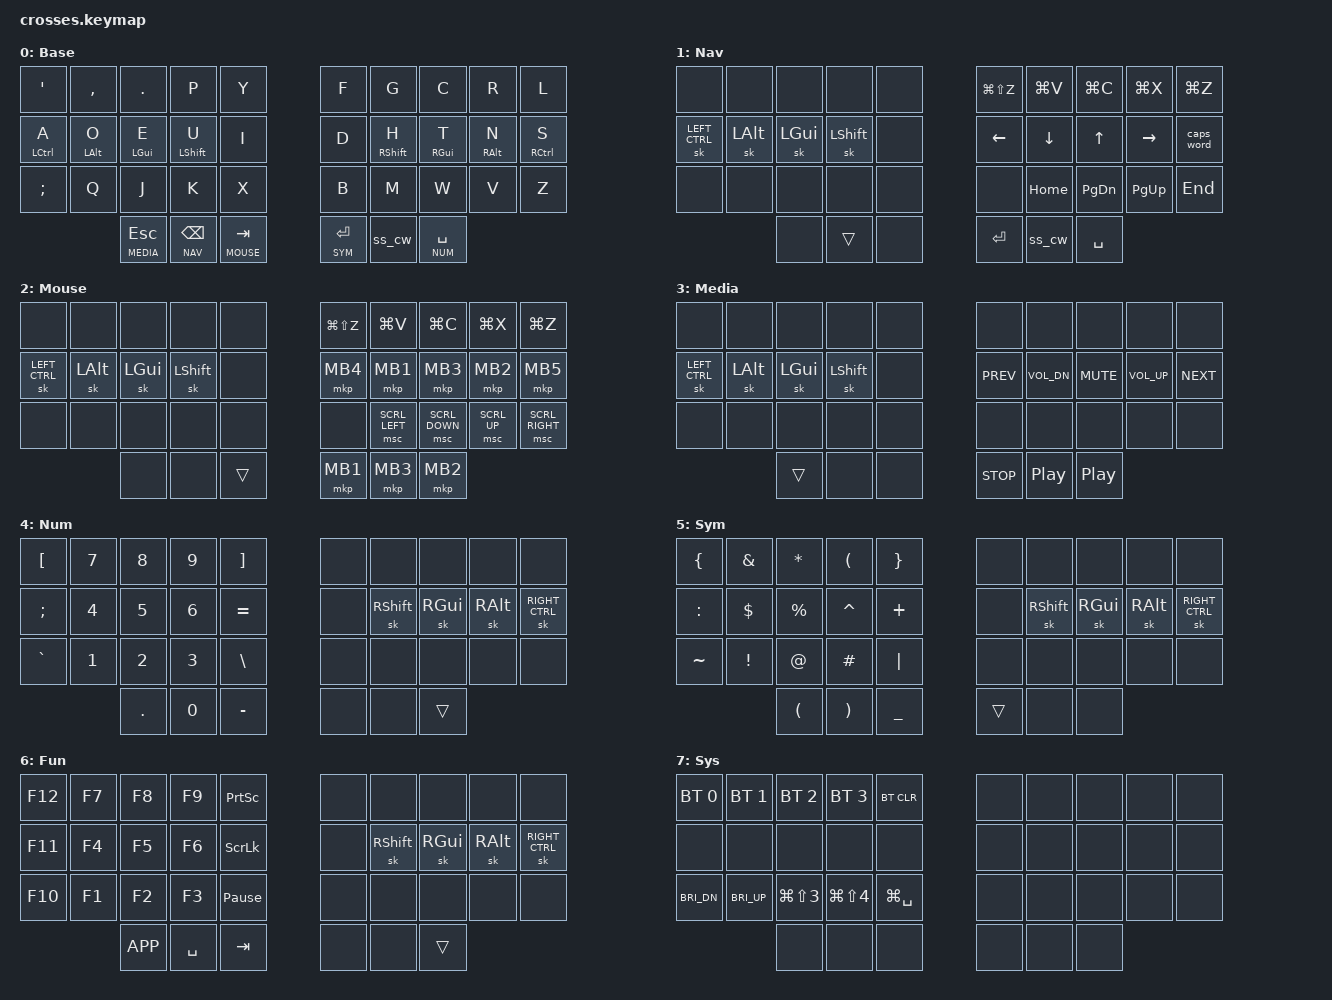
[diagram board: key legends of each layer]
#include <behaviors.dtsi>
#include <dt-bindings/zmk/bt.h>
#include <dt-bindings/zmk/keys.h>
#include <dt-bindings/zmk/pointing.h>

#define BASE  0
#define NAV   1
#define MOUSE 2
#define MEDIA 3
#define NUM   4
#define SYM   5
#define FUN   6
#define SYS   7

#define HM_TAPPING_TERM 280
#define HM_QUICK_TAP    175
#define HM_PRIOR_IDLE   150

/ {
    behaviors {

        hml: homerow_mod_left {
            compatible = "zmk,behavior-hold-tap";
            #binding-cells = <2>;
            flavor = "balanced";
            tapping-term-ms = <HM_TAPPING_TERM>;
            quick-tap-ms = <HM_QUICK_TAP>;
            require-prior-idle-ms = <HM_PRIOR_IDLE>;
            bindings = <&kp>, <&kp>;
            hold-trigger-key-positions = <5 6 7 8 9 15 16 17 18 19 25 26 27 28 29 30 31 32 33 34 35>;
            hold-trigger-on-release;
        };

        hmr: homerow_mod_right {
            compatible = "zmk,behavior-hold-tap";
            #binding-cells = <2>;
            flavor = "balanced";
            tapping-term-ms = <HM_TAPPING_TERM>;
            quick-tap-ms = <HM_QUICK_TAP>;
            require-prior-idle-ms = <HM_PRIOR_IDLE>;
            bindings = <&kp>, <&kp>;
            hold-trigger-key-positions = <0 1 2 3 4 10 11 12 13 14 20 21 22 23 24 30 31 32 33 34 35>;
            hold-trigger-on-release;
        };

        ss_cw: sticky_shift_caps_word {
            compatible = "zmk,behavior-mod-morph";
            #binding-cells = <0>;
            bindings = <&sk LEFT_SHIFT>, <&caps_word>;
            mods = <(MOD_LSFT)>;
        };

        lt_bspc: layer_tap_backspace {
            compatible = "zmk,behavior-hold-tap";
            #binding-cells = <2>;
            flavor = "balanced";
            tapping-term-ms = <200>;
            quick-tap-ms = <HM_QUICK_TAP>;
            bindings = <&mo>, <&kp>;
        };
    };

    conditional_layers {
        compatible = "zmk,conditional-layers";
        sys_layer {
            if-layers = <FUN NUM>;
            then-layer = <SYS>;
        };
    };

    keymap {
        compatible = "zmk,keymap";

        base_layer {
            display-name = "Base";
            bindings = 
   &kp SQT               &kp COMMA           &kp PERIOD          &kp P               &kp Y          &kp F        &kp G               &kp C            &kp R               &kp L
   &hml LEFT_CONTROL A   &hml LEFT_ALT O     &hml LEFT_GUI E     &hml LEFT_SHIFT U   &kp I          &kp D        &hmr RIGHT_SHIFT H  &hmr RIGHT_GUI T &hmr RIGHT_ALT N    &hmr RIGHT_CONTROL S
   &kp SEMICOLON         &kp Q               &kp J               &kp K               &kp X          &kp B        &kp M               &kp W            &kp V               &kp Z
                         &lt MEDIA ESC       &lt_bspc NAV BSPC   &lt MOUSE TAB       &lt SYM RET    &ss_cw       &lt NUM SPACE
            >;
        };

        nav_layer {
            display-name = "Nav";
            bindings = 
   &none          &none         &none         &none           &none    &kp LG(LS(Z))  &kp LG(V)   &kp LG(C)  &kp LG(X)  &kp LG(Z)
   &sk LEFT_CTRL  &sk LEFT_ALT  &sk LEFT_GUI  &sk LEFT_SHIFT  &none    &kp LEFT        &kp DOWN    &kp UP     &kp RIGHT  &caps_word
   &none          &none         &none         &none           &none    &none           &kp HOME    &kp PG_DN  &kp PG_UP  &kp END
                  &none         &trans        &none           &kp RET  &ss_cw          &kp SPACE
            >;
        };

        mouse_layer {
            display-name = "Mouse";
            bindings = 
   &none          &none         &none         &none           &none    &kp LG(LS(Z))  &kp LG(V)      &kp LG(C)       &kp LG(X)      &kp LG(Z)
   &sk LEFT_CTRL  &sk LEFT_ALT  &sk LEFT_GUI  &sk LEFT_SHIFT  &none    &mkp MB4        &mkp MB1       &mkp MB3        &mkp MB2       &mkp MB5
   &none          &none         &none         &none           &none    &none           &msc SCRL_LEFT &msc SCRL_DOWN  &msc SCRL_UP   &msc SCRL_RIGHT
                  &none         &none         &trans          &mkp MB1 &mkp MB3        &mkp MB2
            >;
        };

        media_layer {
            display-name = "Media";
            bindings = 
   &none          &none         &none         &none           &none    &none       &none         &none       &none         &none
   &sk LEFT_CTRL  &sk LEFT_ALT  &sk LEFT_GUI  &sk LEFT_SHIFT  &none    &kp C_PREV  &kp C_VOL_DN  &kp C_MUTE  &kp C_VOL_UP  &kp C_NEXT
   &none          &none         &none         &none           &none    &none       &none         &none       &none         &none
                  &trans        &none         &none           &kp C_STOP &kp C_PLAY_PAUSE &kp C_PP
            >;
        };

        num_layer {
            display-name = "Num";
            bindings = 
   &kp LEFT_BRACKET  &kp N7   &kp N8  &kp N9  &kp RIGHT_BRACKET    &none  &none           &none          &none          &none
   &kp SEMICOLON     &kp N4   &kp N5  &kp N6  &kp EQUAL            &none  &sk RIGHT_SHIFT &sk RIGHT_GUI  &sk RIGHT_ALT  &sk RIGHT_CTRL
   &kp GRAVE         &kp N1   &kp N2  &kp N3  &kp BACKSLASH        &none  &none           &none          &none          &none
                     &kp DOT  &kp N0  &kp MINUS                    &none  &none           &trans
            >;
        };

        sym_layer {
            display-name = "Sym";
            bindings = 
   &kp LEFT_BRACE  &kp AMPERSAND  &kp ASTERISK  &kp LEFT_PARENTHESIS   &kp RIGHT_BRACE    &none   &none           &none          &none          &none
   &kp COLON       &kp DOLLAR     &kp PERCENT   &kp CARET              &kp PLUS           &none   &sk RIGHT_SHIFT &sk RIGHT_GUI  &sk RIGHT_ALT  &sk RIGHT_CTRL
   &kp TILDE       &kp EXCL       &kp AT        &kp HASH               &kp PIPE           &none   &none           &none          &none          &none
                   &kp LEFT_PARENTHESIS  &kp RIGHT_PARENTHESIS  &kp UNDERSCORE   &trans  &none   &none
            >;
        };

        fun_layer {
            display-name = "Fun";
            bindings = 
   &kp F12  &kp F7     &kp F8     &kp F9   &kp PRINTSCREEN    &none  &none           &none          &none          &none
   &kp F11  &kp F4     &kp F5     &kp F6   &kp SCROLLLOCK     &none  &sk RIGHT_SHIFT &sk RIGHT_GUI  &sk RIGHT_ALT  &sk RIGHT_CTRL
   &kp F10  &kp F1     &kp F2     &kp F3   &kp PAUSE_BREAK    &none  &none           &none          &none          &none
            &kp K_APP  &kp SPACE  &kp TAB  &none              &none  &trans
            >;
        };

        sys_layer {
            display-name = "Sys";
            bindings = 
   &bt BT_SEL 0  &bt BT_SEL 1  &bt BT_SEL 2    &bt BT_SEL 3    &bt BT_CLR     &none  &none  &none  &none  &none
   &none          &none          &none            &none            &none          &none  &none  &none  &none  &none
   &kp C_BRI_DN  &kp C_BRI_UP  &kp LG(LS(N3))  &kp LG(LS(N4))  &kp LG(SPACE)  &none  &none  &none  &none  &none
                 &none          &none            &none            &none          &none  &none
            >;
        };
    };
};
